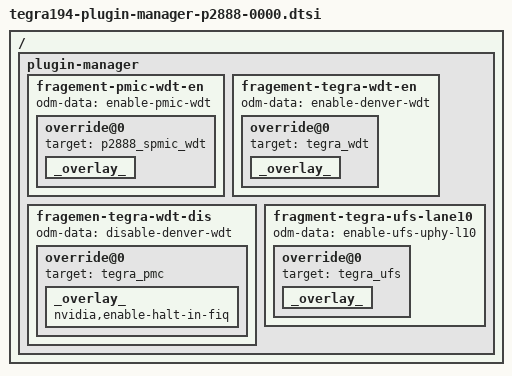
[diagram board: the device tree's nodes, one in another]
/*
 * Copyright (c) 2018-2020, NVIDIA CORPORATION.  All rights reserved.
 *
 * This program is free software; you can redistribute it and/or modify it
 * under the terms and conditions of the GNU General Public License,
 * version 2, as published by the Free Software Foundation.
 *
 * This program is distributed in the hope it will be useful, but WITHOUT
 * ANY WARRANTY; without even the implied warranty of MERCHANTABILITY or
 * FITNESS FOR A PARTICULAR PURPOSE.  See the GNU General Public License for
 * more details.
 *
 * You should have received a copy of the GNU General Public License
 * along with this program.  If not, see <http://www.gnu.org/licenses/>.
 */

#include "tegra194-p2888-p2822-pcie-plugin-manager.dtsi"

/ {
	plugin-manager {
		fragement-pmic-wdt-en {
			odm-data = "enable-pmic-wdt";
			override@0 {
				target = <&p2888_spmic_wdt>;
				_overlay_ {
					status = "okay";
				};
			};
		};

		fragement-tegra-wdt-en {
			odm-data = "enable-denver-wdt";
			override@0 {
				target = <&tegra_wdt>;
				_overlay_ {
					status = "okay";
				};
			};
		};

		fragemen-tegra-wdt-dis {
			odm-data = "disable-denver-wdt";
			override@0 {
				target = <&tegra_pmc>;
				_overlay_ {
					nvidia,enable-halt-in-fiq;
				};
			};
		};

		fragment-tegra-ufs-lane10 {
			odm-data = "enable-ufs-uphy-l10";
			override@0 {
				target = <&tegra_ufs>;
				_overlay_ {
					status = "okay";
				};
			};
		};
	};
};
